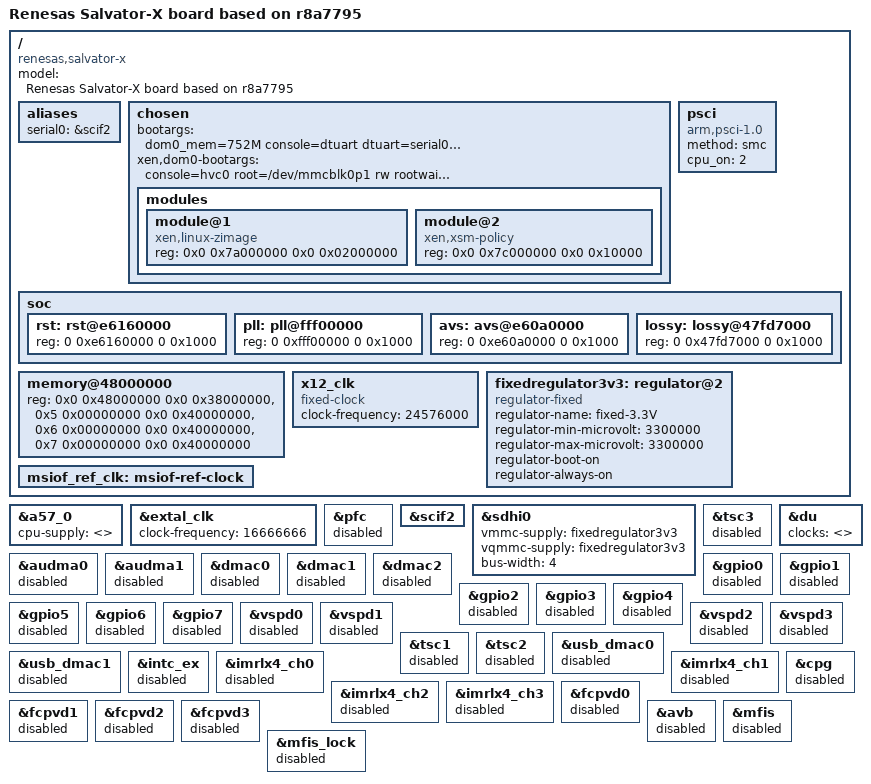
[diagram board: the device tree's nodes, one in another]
/*
 * Device Tree Source for the Salvator-X board
 *
 * Copyright (C) 2015-2016 Renesas Electronics Corp.
 *
 * This file is licensed under the terms of the GNU General Public License
 * version 2.  This program is licensed "as is" without any warranty of any
 * kind, whether express or implied.
 */

/*
 * SSI-AK4613
 *
 * This command is required when Playback/Capture
 *
 *	amixer set "DVC Out" 100%
 *	amixer set "DVC In" 100%
 *
 * You can use Mute
 *
 *	amixer set "DVC Out Mute" on
 *	amixer set "DVC In Mute" on
 *
 * You can use Volume Ramp
 *
 *	amixer set "DVC Out Ramp Up Rate"   "0.125 dB/64 steps"
 *	amixer set "DVC Out Ramp Down Rate" "0.125 dB/512 steps"
 *	amixer set "DVC Out Ramp" on
 *	aplay xxx.wav &
 *	amixer set "DVC Out"  80%  // Volume Down
 *	amixer set "DVC Out" 100%  // Volume Up
 */

/dts-v1/;
#include "r8a7795.dtsi"
#include <dt-bindings/gpio/gpio.h>

/ {
	model = "Renesas Salvator-X board based on r8a7795";
	compatible = "renesas,salvator-x", "renesas,r8a7795";

	aliases {
		serial0 = &scif2;
	};

	chosen {
		bootargs = "dom0_mem=752M console=dtuart dtuart=serial0 dom0_max_vcpus=4 bootscrub=0 flask_enforcing=1 loglvl=all";
		xen,dom0-bootargs = "console=hvc0 root=/dev/mmcblk0p1 rw rootwait rootfstype=ext4 ignore_loglevel cma=128M";
		modules {
			#address-cells = <2>;
			#size-cells = <2>;
			module@1 {
				compatible = "xen,linux-zimage", "xen,multiboot-module";
				reg = <0x0 0x7a000000 0x0 0x02000000>;
			};
			module@2 {
				compatible = "xen,xsm-policy", "xen,multiboot-module";
				reg = <0x0 0x7c000000 0x0 0x10000>;
			};
		};
	};

	psci {
		compatible = "arm,psci-1.0";
		method = "smc";
		cpu_on = <2>;
	};

	soc{
		rst: rst@e6160000 {
			reg = <0 0xe6160000 0 0x1000>;
		};

		pll: pll@fff00000 {
			reg = <0 0xfff00000 0 0x1000>;
		};

		avs: avs@e60a0000 {
			reg = <0 0xe60a0000 0 0x1000>;
		};

		lossy: lossy@47fd7000 {
			reg = <0 0x47fd7000 0 0x1000>;
		};
	};

	memory@48000000 {
		device_type = "memory";
		/* first 128MB is reserved for secure area. */
		reg = <0x0 0x48000000 0x0 0x38000000>,
		      <0x5 0x00000000 0x0 0x40000000>,
		      <0x6 0x00000000 0x0 0x40000000>,
		      <0x7 0x00000000 0x0 0x40000000>;
	};

	x12_clk: x12_clk {
		compatible = "fixed-clock";
		#clock-cells = <0>;
		clock-frequency = <24576000>;
	};

	fixedregulator3v3: regulator@2 {
		compatible = "regulator-fixed";
		regulator-name = "fixed-3.3V";
		regulator-min-microvolt = <3300000>;
		regulator-max-microvolt = <3300000>;
		regulator-boot-on;
		regulator-always-on;
	};

	msiof_ref_clk: msiof-ref-clock {
	/* Dummy clk node to keep dtc happy. This would be unused in runtime */
	};
};

&a57_0 {
	cpu-supply = <>;
};

&extal_clk {
	clock-frequency = <16666666>;
};

&pfc {
	status = "disabled";
};

&scif2 {
	status = "okay";
};

&sdhi0 {
	vmmc-supply = <&fixedregulator3v3>;
	vqmmc-supply = <&fixedregulator3v3>;

	/delete-property/power-domains;
	/delete-property/clocks;

	bus-width = <4>;
	status = "okay";
};

&tsc3 {
	status = "disabled";
};

&du {
	clocks = <>;
};

&audma0 {
	status = "disabled";
};

&audma1 {
	status = "disabled";
};

&dmac0 {
	status = "disabled";
};

&dmac1 {
	status = "disabled";
};

&dmac2 {
	status = "disabled";
};

&gpio0 {
	status = "disabled";
};

&gpio1 {
	status = "disabled";
};

&gpio2 {
	status = "disabled";
};

&gpio3 {
	status = "disabled";
};

&gpio4 {
	status = "disabled";
};

&gpio5 {
	status = "disabled";
};

&gpio6 {
	status = "disabled";
};

&gpio7 {
	status = "disabled";
};

&vspd0 {
	status = "disabled";
};

&vspd1 {
	status = "disabled";
};

&vspd2 {
	status = "disabled";
};

&vspd3 {
	status = "disabled";
};

&tsc1 {
	status = "disabled";
};

&tsc2 {
	status = "disabled";
};

&usb_dmac0 {
	status = "disabled";
};

&usb_dmac1 {
	status = "disabled";
};

&intc_ex {
	status = "disabled";
};

&imrlx4_ch0 {
	status = "disabled";
};

&imrlx4_ch1 {
	status = "disabled";
};

&imrlx4_ch2 {
	status = "disabled";
};

&imrlx4_ch3 {
	status = "disabled";
};

&cpg {
	status = "disabled";
};

&fcpvd0 {
	status = "disabled";
};

&fcpvd1 {
	status = "disabled";
};

&fcpvd2 {
	status = "disabled";
};

&fcpvd3 {
	status = "disabled";
};

&avb {
	status = "disabled";
};

&mfis  {
	status = "disabled";
};

&mfis_lock {
	status = "disabled";
};

